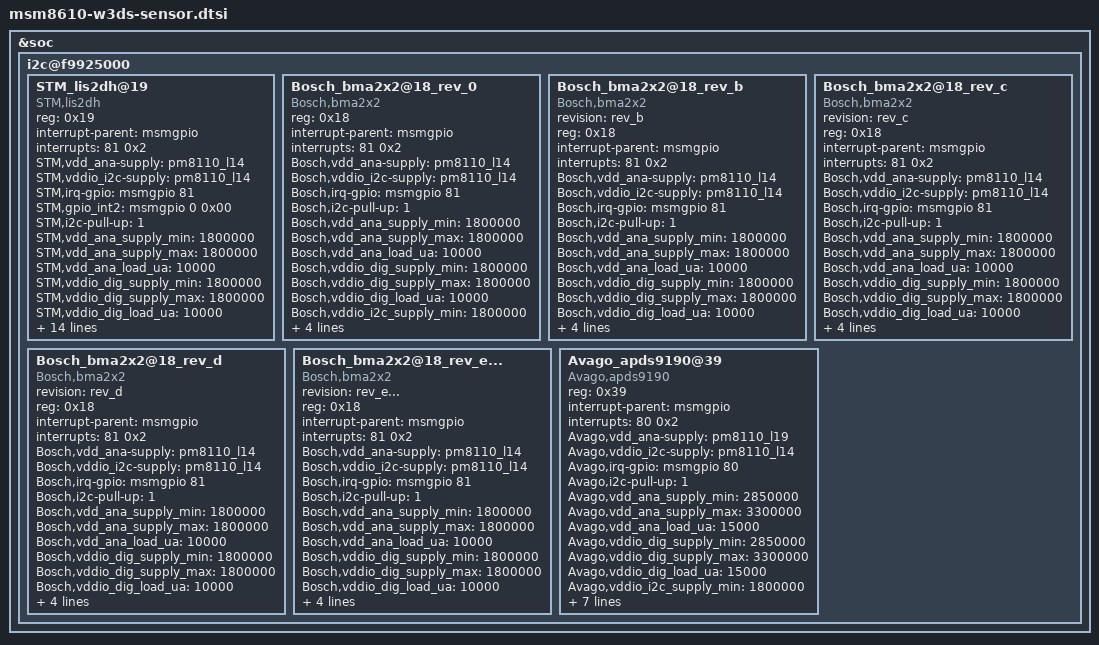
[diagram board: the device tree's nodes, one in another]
/* Copyright (c) 2012, Code Aurora Forum. All rights reserved.
 *
 * This program is free software; you can redistribute it and/or modify
 * it under the terms of the GNU General Public License version 2 and
 * only version 2 as published by the Free Software Foundation.
 *
 * This program is distributed in the hope that it will be useful,
 * but WITHOUT ANY WARRANTY; without even the implied warranty of
 * MERCHANTABILITY or FITNESS FOR A PARTICULAR PURPOSE.  See the
 * GNU General Public License for more details.
 */

&soc {
	/* I2C device */
	i2c@f9925000 {
		/* Acceleration sensor */
		STM_lis2dh@19{
			compatible = "STM,lis2dh";
			reg = <0x19>;
			interrupt-parent = <&msmgpio>;
			interrupts = <81 0x2>;
			STM,vdd_ana-supply = <&pm8110_l14>;
			STM,vddio_i2c-supply = <&pm8110_l14>;
			STM,irq-gpio = <&msmgpio 81 0x00>;
			STM,gpio_int2 = <&msmgpio 0 0x00>;
			STM,i2c-pull-up = <1>;
			STM,vdd_ana_supply_min = <1800000>;
			STM,vdd_ana_supply_max = <1800000>;
			STM,vdd_ana_load_ua = <10000>;
			STM,vddio_dig_supply_min = <1800000>;
			STM,vddio_dig_supply_max = <1800000>;
			STM,vddio_dig_load_ua = <10000>;
			STM,vddio_i2c_supply_min = <1800000>;
			STM,vddio_i2c_supply_max = <1800000>;
			STM,vddio_i2c_load_ua = <10000>;
			STM,fs_range = <0x00>;
			STM,axis_map_x = <1>;
			STM,axis_map_y = <0>;
			STM,axis_map_z = <2>;
			STM,negate_x = <1>;
			STM,negate_y = <1>;
			STM,negate_z = <1>;
			STM,poll_interval = <100>;
			STM,min_interval = <1>;
			place = <5>;
			status = "ok";
			revision = "rev_a";
		};
		Bosch_bma2x2@18_rev_0{
			compatible = "Bosch,bma2x2";
			reg = <0x18>;
			interrupt-parent = <&msmgpio>;
			interrupts = <81 0x2>;
			Bosch,vdd_ana-supply = <&pm8110_l14>;
			Bosch,vddio_i2c-supply = <&pm8110_l14>;
			Bosch,irq-gpio = <&msmgpio 81 0x00>;
			Bosch,i2c-pull-up = <1>;
			Bosch,vdd_ana_supply_min = <1800000>;
			Bosch,vdd_ana_supply_max = <1800000>;
			Bosch,vdd_ana_load_ua = <10000>;
			Bosch,vddio_dig_supply_min = <1800000>;
			Bosch,vddio_dig_supply_max = <1800000>;
			Bosch,vddio_dig_load_ua = <10000>;
			Bosch,vddio_i2c_supply_min = <1800000>;
			Bosch,vddio_i2c_supply_max = <1800000>;
			Bosch,vddio_i2c_load_ua = <10000>;
			place = <5>;
			status = "ok";
			revision = "rev_0";
		};
		Bosch_bma2x2@18_rev_b{
			compatible = "Bosch,bma2x2";
			revision = "rev_b";
			status = "ok";
			reg = <0x18>;
			interrupt-parent = <&msmgpio>;
			interrupts = <81 0x2>;
			Bosch,vdd_ana-supply = <&pm8110_l14>;
			Bosch,vddio_i2c-supply = <&pm8110_l14>;
			Bosch,irq-gpio = <&msmgpio 81 0x00>;
			Bosch,i2c-pull-up = <1>;
			Bosch,vdd_ana_supply_min = <1800000>;
			Bosch,vdd_ana_supply_max = <1800000>;
			Bosch,vdd_ana_load_ua = <10000>;
			Bosch,vddio_dig_supply_min = <1800000>;
			Bosch,vddio_dig_supply_max = <1800000>;
			Bosch,vddio_dig_load_ua = <10000>;
			Bosch,vddio_i2c_supply_min = <1800000>;
			Bosch,vddio_i2c_supply_max = <1800000>;
			Bosch,vddio_i2c_load_ua = <10000>;
			place = <7>;
		};
		Bosch_bma2x2@18_rev_c{
			compatible = "Bosch,bma2x2";
			revision = "rev_c";
			status = "ok";
			reg = <0x18>;
			interrupt-parent = <&msmgpio>;
			interrupts = <81 0x2>;
			Bosch,vdd_ana-supply = <&pm8110_l14>;
			Bosch,vddio_i2c-supply = <&pm8110_l14>;
			Bosch,irq-gpio = <&msmgpio 81 0x00>;
			Bosch,i2c-pull-up = <1>;
			Bosch,vdd_ana_supply_min = <1800000>;
			Bosch,vdd_ana_supply_max = <1800000>;
			Bosch,vdd_ana_load_ua = <10000>;
			Bosch,vddio_dig_supply_min = <1800000>;
			Bosch,vddio_dig_supply_max = <1800000>;
			Bosch,vddio_dig_load_ua = <10000>;
			Bosch,vddio_i2c_supply_min = <1800000>;
			Bosch,vddio_i2c_supply_max = <1800000>;
			Bosch,vddio_i2c_load_ua = <10000>;
			place = <5>;
		};
		Bosch_bma2x2@18_rev_d{
			compatible = "Bosch,bma2x2";
			revision = "rev_d";
			status = "ok";
			reg = <0x18>;
			interrupt-parent = <&msmgpio>;
			interrupts = <81 0x2>;
			Bosch,vdd_ana-supply = <&pm8110_l14>;
			Bosch,vddio_i2c-supply = <&pm8110_l14>;
			Bosch,irq-gpio = <&msmgpio 81 0x00>;
			Bosch,i2c-pull-up = <1>;
			Bosch,vdd_ana_supply_min = <1800000>;
			Bosch,vdd_ana_supply_max = <1800000>;
			Bosch,vdd_ana_load_ua = <10000>;
			Bosch,vddio_dig_supply_min = <1800000>;
			Bosch,vddio_dig_supply_max = <1800000>;
			Bosch,vddio_dig_load_ua = <10000>;
			Bosch,vddio_i2c_supply_min = <1800000>;
			Bosch,vddio_i2c_supply_max = <1800000>;
			Bosch,vddio_i2c_load_ua = <10000>;
			place = <7>;
		};
		Bosch_bma2x2@18_rev_e...{
			compatible = "Bosch,bma2x2";
			revision = "rev_e...";
			status = "ok";
			reg = <0x18>;
			interrupt-parent = <&msmgpio>;
			interrupts = <81 0x2>;
			Bosch,vdd_ana-supply = <&pm8110_l14>;
			Bosch,vddio_i2c-supply = <&pm8110_l14>;
			Bosch,irq-gpio = <&msmgpio 81 0x00>;
			Bosch,i2c-pull-up = <1>;
			Bosch,vdd_ana_supply_min = <1800000>;
			Bosch,vdd_ana_supply_max = <1800000>;
			Bosch,vdd_ana_load_ua = <10000>;
			Bosch,vddio_dig_supply_min = <1800000>;
			Bosch,vddio_dig_supply_max = <1800000>;
			Bosch,vddio_dig_load_ua = <10000>;
			Bosch,vddio_i2c_supply_min = <1800000>;
			Bosch,vddio_i2c_supply_max = <1800000>;
			Bosch,vddio_i2c_load_ua = <10000>;
			place = <5>;
		};
		/* Proximity sensor */
		Avago_apds9190@39 {
			compatible = "Avago,apds9190";
			reg = <0x39>;
			interrupt-parent = <&msmgpio>;
			interrupts = <80 0x2>;
			Avago,vdd_ana-supply = <&pm8110_l19>;
			Avago,vddio_i2c-supply = <&pm8110_l14>;
			Avago,irq-gpio = <&msmgpio 80 0x00>;
			Avago,i2c-pull-up = <1>;
			Avago,vdd_ana_supply_min = <2850000>;
			Avago,vdd_ana_supply_max = <3300000>;
			Avago,vdd_ana_load_ua = <15000>;
			Avago,vddio_dig_supply_min = <2850000>;
			Avago,vddio_dig_supply_max = <3300000>;
			Avago,vddio_dig_load_ua = <15000>;
			Avago,vddio_i2c_supply_min = <1800000>;
			Avago,vddio_i2c_supply_max = <1800000>;
			Avago,vddio_i2c_load_ua = <10000>;
			Avago,ppcount = <8>;
			Avago,pdrive = <0>;
			Avago,near_offset = <250>;
			Avago,far_offset = <80>;
			Avago,crosstalk_max = <770>;
			status = "ok";
		};
	};
};
